# STM32L443 register map
File version: 1.0
CPU: CM4 r0p1, little endian, MPU, FPU, 4 interrupt priority bits
Registers are 32-bit, read-write, reset 0x0 unless marked. A register's access mark holds for its fields unless they carry their own. Offsets are from the block's base; [hi:lo] are bit positions; {n}, {i} and the like mark numbered series.

## OPAMP — Operational amplifiers
Base 0x40007800
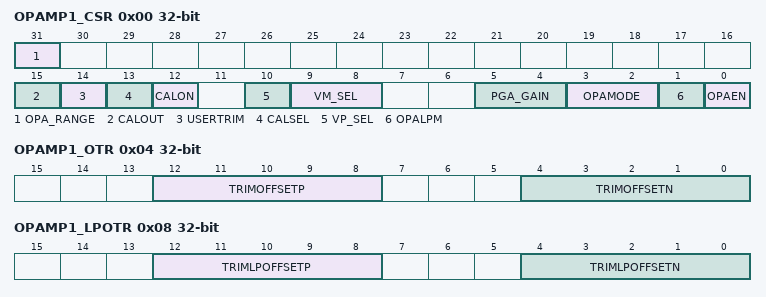
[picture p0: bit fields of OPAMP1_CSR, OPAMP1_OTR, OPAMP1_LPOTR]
0x00 OPAMP1_CSR — OPAMP1 control/status register
  [31] OPA_RANGE — Operational amplifier power supply range for stability
  [15] CALOUT — Operational amplifier calibration output
  [14] USERTRIM — allows to switch from factory AOP offset trimmed values to AOP offset user trimmed values
  [13] CALSEL — Calibration selection
  [12] CALON — Calibration mode enabled
  [10] VP_SEL — Non inverted input selection
  [9:8] VM_SEL — Inverting input selection
  [5:4] PGA_GAIN — Operational amplifier Programmable amplifier gain value
  [3:2] OPAMODE — Operational amplifier PGA mode
  [1] OPALPM — Operational amplifier Low Power Mode
  [0] OPAEN — Operational amplifier Enable
0x04 OPAMP1_OTR — OPAMP1 offset trimming register in normal mode
  [12:8] TRIMOFFSETP — Trim for PMOS differential pairs
  [4:0] TRIMOFFSETN — Trim for NMOS differential pairs
0x08 OPAMP1_LPOTR — OPAMP1 offset trimming register in low-power mode
  [12:8] TRIMLPOFFSETP — Trim for PMOS differential pairs
  [4:0] TRIMLPOFFSETN — Trim for NMOS differential pairs

## CRS — Clock recovery system
Base 0x40006000
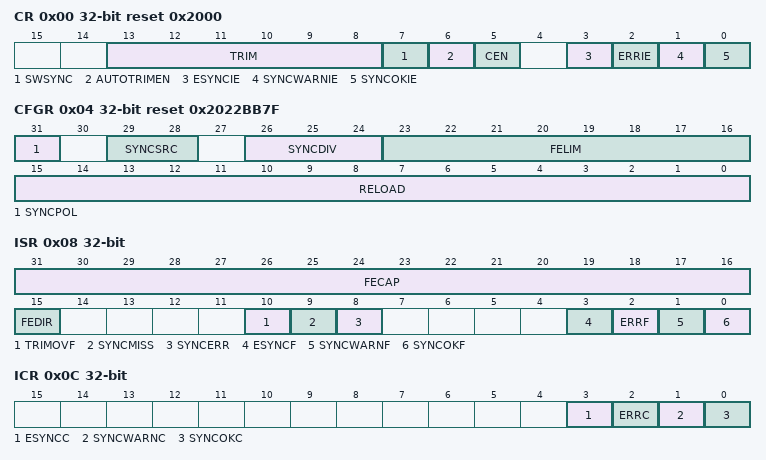
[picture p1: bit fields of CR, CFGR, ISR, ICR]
0x00 CR reset 0x2000 — control register
  [13:8] TRIM — HSI48 oscillator smooth trimming
  [7] SWSYNC — Generate software SYNC event
  [6] AUTOTRIMEN — Automatic trimming enable
  [5] CEN — Frequency error counter enable
  [3] ESYNCIE — Expected SYNC interrupt enable
  [2] ERRIE — Synchronization or trimming error interrupt enable
  [1] SYNCWARNIE — SYNC warning interrupt enable
  [0] SYNCOKIE — SYNC event OK interrupt enable
0x04 CFGR reset 0x2022BB7F — configuration register
  [31] SYNCPOL — SYNC polarity selection
  [29:28] SYNCSRC — SYNC signal source selection
  [26:24] SYNCDIV — SYNC divider
  [23:16] FELIM — Frequency error limit
  [15:0] RELOAD — Counter reload value
0x08 ISR ro — interrupt and status register
  [31:16] FECAP — Frequency error capture
  [15] FEDIR — Frequency error direction
  [10] TRIMOVF — Trimming overflow or underflow
  [9] SYNCMISS — SYNC missed
  [8] SYNCERR — SYNC error
  [3] ESYNCF — Expected SYNC flag
  [2] ERRF — Error flag
  [1] SYNCWARNF — SYNC warning flag
  [0] SYNCOKF — SYNC event OK flag
0x0C ICR — interrupt flag clear register
  [3] ESYNCC — Expected SYNC clear flag
  [2] ERRC — Error clear flag
  [1] SYNCWARNC — SYNC warning clear flag
  [0] SYNCOKC — SYNC event OK clear flag

## USB_SRAM — Universal serial bus full-speed device interface
Base 0x40006C00
Same registers: USB_FS 0x40006800
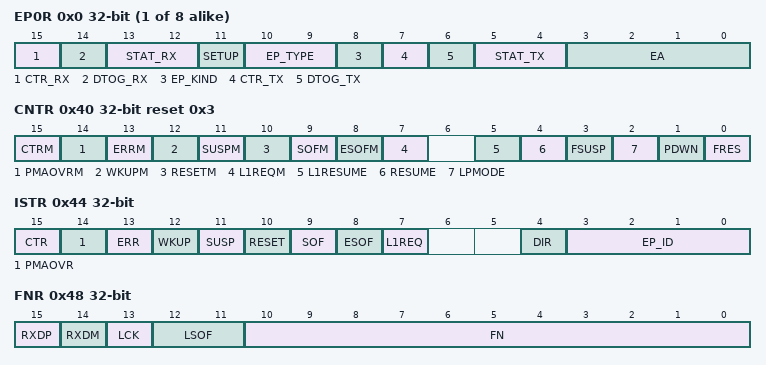
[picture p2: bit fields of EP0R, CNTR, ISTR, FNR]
{0x0+4i} EP{i}R (i=0..7) — endpoint {i} register
  [15] CTR_RX — Correct transfer for reception
  [14] DTOG_RX — Data Toggle, for reception transfers
  [13:12] STAT_RX — Status bits, for reception transfers
  [11] SETUP — Setup transaction completed
  [10:9] EP_TYPE — Endpoint type
  [8] EP_KIND — Endpoint kind
  [7] CTR_TX — Correct Transfer for transmission
  [6] DTOG_TX — Data Toggle, for transmission transfers
  [5:4] STAT_TX — Status bits, for transmission transfers
  [3:0] EA — Endpoint address
0x40 CNTR reset 0x3 — control register
  [15] CTRM — Correct transfer interrupt mask
  [14] PMAOVRM — Packet memory area over / underrun interrupt mask
  [13] ERRM — Error interrupt mask
  [12] WKUPM — Wakeup interrupt mask
  [11] SUSPM — Suspend mode interrupt mask
  [10] RESETM — USB reset interrupt mask
  [9] SOFM — Start of frame interrupt mask
  [8] ESOFM — Expected start of frame interrupt mask
  [7] L1REQM — LPM L1 state request interrupt mask
  [5] L1RESUME — LPM L1 Resume request
  [4] RESUME — Resume request
  [3] FSUSP — Force suspend
  [2] LPMODE — Low-power mode
  [1] PDWN — Power down
  [0] FRES — Force USB Reset
0x44 ISTR access per field — interrupt status register
  [15] CTR ro — Correct transfer
  [14] PMAOVR rw — Packet memory area over / underrun
  [13] ERR rw — Error
  [12] WKUP rw — Wakeup
  [11] SUSP rw — Suspend mode request
  [10] RESET rw — reset request
  [9] SOF rw — start of frame
  [8] ESOF rw — Expected start frame
  [7] L1REQ rw — LPM L1 state request
  [4] DIR ro — Direction of transaction
  [3:0] EP_ID ro — Endpoint Identifier
0x48 FNR ro — frame number register
  [15] RXDP — Receive data + line status
  [14] RXDM — Receive data - line status
  [13] LCK — Locked
  [12:11] LSOF — Lost SOF
  [10:0] FN — Frame number
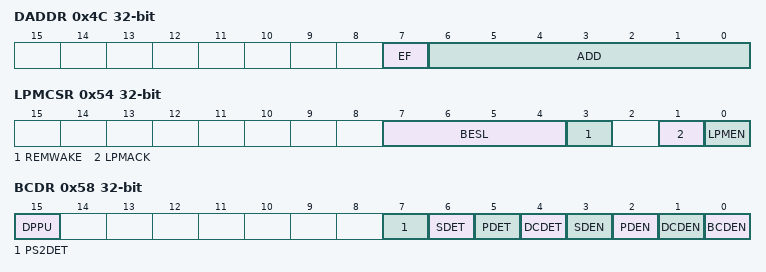
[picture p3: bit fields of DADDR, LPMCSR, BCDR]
0x4C DADDR — device address
  [7] EF — Enable function
  [6:0] ADD — Device address
0x50 BTABLE — Buffer table address
  [15:3] BTABLE — Buffer table
0x54 LPMCSR access per field — LPM control and status register
  [7:4] BESL ro — BESL value
  [3] REMWAKE ro — bRemoteWake value
  [1] LPMACK rw — LPM Token acknowledge enable
  [0] LPMEN rw — LPM support enable
0x58 BCDR access per field — Battery charging detector
  [15] DPPU rw — DP pull-up control
  [7] PS2DET ro — DM pull-up detection status
  [6] SDET ro — Secondary detection
  [5] PDET ro — Primary detection
  [4] DCDET ro — Data contact detection
  [3] SDEN rw — Secondary detection
  [2] PDEN rw — Primary detection
  [1] DCDEN rw — Data contact detection
  [0] BCDEN rw — Battery charging detector

## DBGMCU — MCU debug component
Base 0xE0042000
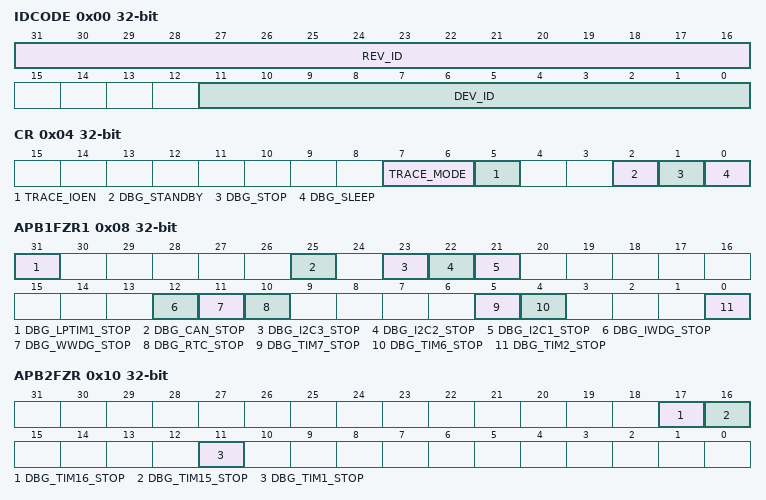
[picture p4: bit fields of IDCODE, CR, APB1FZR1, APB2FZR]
0x00 IDCODE ro — DBGMCU_IDCODE
  [31:16] REV_ID — Revision identifie
  [11:0] DEV_ID — Device identifier
0x04 CR — Debug MCU configuration register
  [7:6] TRACE_MODE — Trace pin assignment control
  [5] TRACE_IOEN — Trace pin assignment control
  [2] DBG_STANDBY — Debug Standby mode
  [1] DBG_STOP — Debug Stop mode
  [0] DBG_SLEEP — Debug Sleep mode
0x08 APB1FZR1 — Debug MCU APB1 freeze register1
  [31] DBG_LPTIM1_STOP — LPTIM1 counter stopped when core is halted
  [25] DBG_CAN_STOP — bxCAN stopped when core is halted
  [23] DBG_I2C3_STOP — I2C3 SMBUS timeout counter stopped when core is halted
  [22] DBG_I2C2_STOP — I2C2 SMBUS timeout counter stopped when core is halted
  [21] DBG_I2C1_STOP — I2C1 SMBUS timeout counter stopped when core is halted
  [12] DBG_IWDG_STOP — Independent watchdog counter stopped when core is halted
  [11] DBG_WWDG_STOP — Window watchdog counter stopped when core is halted
  [10] DBG_RTC_STOP — RTC counter stopped when core is halted
  [5] DBG_TIM7_STOP — TIM7 counter stopped when core is halted
  [4] DBG_TIM6_STOP — TIM6 counter stopped when core is halted
  [0] DBG_TIM2_STOP — TIM2 counter stopped when core is halted
0x0C APB1FZR2 — Debug MCU APB1 freeze register 2
  [5] DBG_LPTIM2_STOP — LPTIM2 counter stopped when core is halted
0x10 APB2FZR — Debug MCU APB2 freeze register
  [17] DBG_TIM16_STOP — TIM16 counter stopped when core is halted
  [16] DBG_TIM15_STOP — TIM15 counter stopped when core is halted
  [11] DBG_TIM1_STOP — TIM1 counter stopped when core is halted

## Notices in the file
Copyright (c) 2024 STMicroelectronics.
SPDX-License-Identifier: Apache-2.0
Licensed under the Apache License, Version 2.0 (the "License");
you may not use this file except in compliance with the License.
You may obtain a copy of the License at
http://www.apache.org/licenses/LICENSE-2.0
Unless required by applicable law or agreed to in writing, software
distributed under the License is distributed on an "AS IS" BASIS,
WITHOUT WARRANTIES OR CONDITIONS OF ANY KIND, either express or implied.
See the License for the specific language governing permissions and
limitations under the License.
